# I2C_0 register map
Vendor: Texas Instruments
Peripheral module from a debugger description file (folder 66AK2G0x_66AK2G1x).
Registers are 32-bit, access per field, reset 0x0 unless marked. A register's access mark holds for its fields unless they carry their own. Offsets are as the file gives them; lines under a group give offsets from that group; [hi:lo] are bit positions; {n}, {i} and the like mark numbered series; 'fields as' and 'values as' point back to an identical list; <NAME> marks a mode.

## I2C_0
0x00 I2C_ICOAR
  [9:0] OADDR rw — Value = 0-3FFhOwn slave address. Provides the slave address of the I In 7-bit addressing mode (XA = 0 in Bits 9-7 are ignored. In 10-bit addressing mode (XA = 1 in
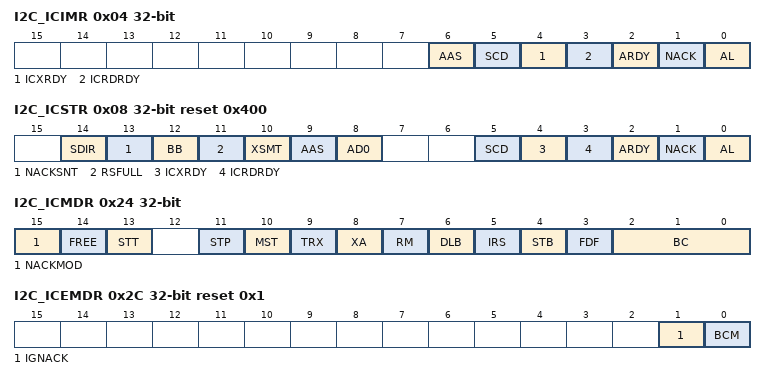
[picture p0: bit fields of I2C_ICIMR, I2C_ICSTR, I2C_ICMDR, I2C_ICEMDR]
0x04 I2C_ICIMR
  [6] AAS rw — Address-as-slave interrupt enable bit.
  [5] SCD rw — Stop condition detected interrupt enable bit.
  [4] ICXRDY rw — Transmit-data-ready interrupt enable bit.
  [3] ICRDRDY rw — Receive-data-ready interrupt enable bit.
  [2] ARDY rw — Register-access-ready interrupt enable bit.
  [1] NACK rw — No-acknowledgment interrupt enable bit.
  [0] AL rw — Arbitration-lost interrupt enable bit.
0x08 I2C_ICSTR access not given reset 0x400
  [14] SDIR — Slave direction bit. In digital-loopback mode (DLB), the SDIR bit is cleared to 0. (access RW1toCl)
  [13] NACKSNT — No-acknowledgment sent bit. NACKSNT bit is used when the I (access RW1toCl)
  [12] BB — Bus busy bit. BB bit indicates whether the I (access RW1toCl)
  [11] RSFULL ro — Receive shift register full bit. RSFULL indicates an overrun condition during reception. Overrun occurs when the receive shift register ICRSR is full with new data but the previous data has not been read from the data receive register
  [10] XSMT rw — Underflow occurs when the transmit shift register ICXSR is empty but the data transmit register
  [9] AAS ro — Addressed-as-slave bit.
  [8] AD0 ro — Address 0 bit.
  [5] SCD — Stop condition detected bit. SCD indicates when a STOP condition has been detected on the I (access RW1toCl)
  [4] ICXRDY — Transmit-data-ready interrupt flag bit. ICXRDY indicates that the data transmit register (access RW1toCl)
  [3] ICRDRDY — Receive-data-ready interrupt flag bit. ICRDRDY indicates that the data receive register (access RW1toCl)
  [2] ARDY — Register-access-ready interrupt flag bit (only applicable when the I (access RW1toCl)
  [1] NACK — No-acknowledgment interrupt flag bit. NACK applies when the I Note: While the I (access RW1toCl)
  [0] AL — Arbitration-lost interrupt flag bit (only applicable when the I When AL is set to 1, the MST and STP bits of (access RW1toCl)
0x0C I2C_ICCLKL
  [15:0] ICCL rw — Value = 0-FFFFhClock low-time divide-down value of 1-65536. The period of the module clock is multiplied by (ICCL + 6) to produce the low-time duration of the master clock on the SCL pin.
0x10 I2C_ICCLKH
  [15:0] ICCH rw — Value = 0-FFFFhClock high-time divide-down value of 1-65536. The period of the module clock is multiplied by (ICCH + 6) to produce the high-time duration of the master clock on the SCL pin.
0x14 I2C_ICCNT
  [15:0] ICDC rw — Value = 0-FFFFhData count value. When RM = 0 in
0x18 I2C_ICDRR ro
  [7:0] D — Value = 0-FFhReceive data.
0x1C I2C_ICSAR reset 0x3FF
  [9:0] SADDR rw — Value = 0-3FFhSlave address. Provides the slave address of the I In 7-bit addressing mode (XA = 0 in In 10-bit addressing mode (XA = 1 in
0x20 I2C_ICDXR
  [7:0] D rw — Value = 0-FFhTransmit data.
0x24 I2C_ICMDR
  [15] NACKMOD rw — No-acknowledge (NACK) mode bit (only applicable when the I
  [14] FREE rw — This emulation mode bit is used to determine the state of the I
  [13] STT rw — START condition bit (only applicable when the I
  [11] STP rw — STOP condition bit (only applicable when the I
  [10] MST rw — Master mode bit. MST determines whether the I
  [9] TRX rw — Transmitter mode bit. When relevant, TRX selects whether the I
  [8] XA rw — Expanded address enable bit.
  [7] RM rw — Repeat mode bit (only applicable when the I
  [6] DLB rw — Digital loopback mode bit (only applicable when the I n = ((I The transmit clock is also the receive clock. The address transmitted on the SDA pin is the address in
  [5] IRS rw — I
  [4] STB rw — START byte mode bit (only applicable when the I 1. A START condition 2. A START byte (0000 0001b) 3. A dummy acknowledge clock pulse 4. A repeated START condition The I
  [3] FDF rw — Free data format mode bit. Note that DLB mode in the free data format mode (DLB = 1 and FDF = 1) is not supported (see
  [2:0] BC rw — Bit count bits. BC defines the number of bits (1 to 8) in the next data word that is to be received or transmitted by the I If the bit count is less than 8, receive data is right aligned in the D bits of
0x28 I2C_ICIVR ro
  [2:0] INTCODE — Value = 0-7hInterrupt code bits. The binary code in INTCODE indicates which event generated an I
0x2C I2C_ICEMDR reset 0x1
  [1] IGNACK rw — Ignore NACK mode.
  [0] BCM rw — Backward compatibility mode bit. Determines which condition generates a transmit data ready interrupt. The BCM bit has an effect only when the I
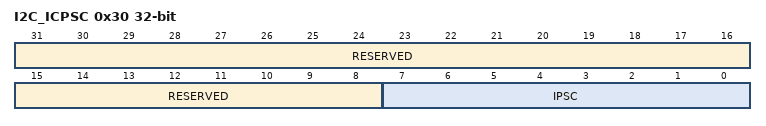
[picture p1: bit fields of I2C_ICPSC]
0x30 I2C_ICPSC
  [31:8] RESERVED ro — Value = 0
  [7:0] IPSC rw — Value = 0-FFh Note: IPSC must be initialized while the I
0x34 I2C_ICPID1 ro reset 0x4415
  [31:0] REV — TI internal data. Identifies revision of peripheral.
0x38 I2C_ICPID2 ro reset 0x2206
  [31:0] RESERVED — TI internal data. Identifies revision of peripheral.
